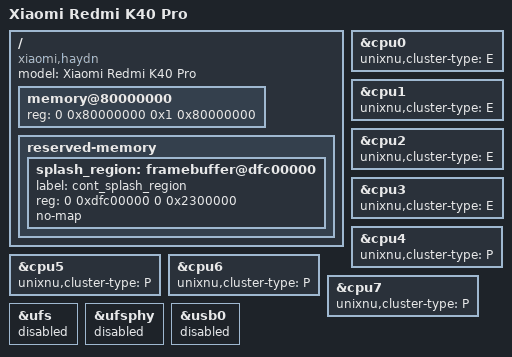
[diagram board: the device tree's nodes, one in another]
// SPDX-License-Identifier: BSD-3-Clause
// Xiaomi Redmi K40 Pro / K40 Pro+ / Mi 11i (haydn), Qualcomm SM8350.
// Hardware values come from the device's own firmware FDT (/sys/firmware/fdt)
// and the on-device GPT; see docs/haydn-hardware.md.
/dts-v1/;
/include/ "sm8350.dtsi"

/ {
    model = "Xiaomi Redmi K40 Pro";
    compatible = "xiaomi,haydn", "qcom,sm8350";
    // Restated here: with the legacy /include/ directive dtc parses this
    // file's nodes before it has merged the included root, so a 64-bit "reg"
    // size below would be truncated to 32 bits without these two lines.
    #address-cells = <2>;
    #size-cells = <2>;

    memory@80000000 {
        device_type = "memory";
        // The ADT window published to XNU. The board has 12 GiB split as
        // 0x80000000+0x37500000, 0xc0000000+0x140000000, 0x200000000+0x180000000.
        // One flat 6 GiB window from 0x80000000 stays inside real DRAM and
        // matches [payload] dram_size (mkadt rejects a mismatch).
        // 0x180000000 needs 33 bits, so it is written as two cells:
        // <address-hi address-lo size-hi size-lo>.
        reg = <0 0x80000000 0x1 0x80000000>;
    };

    reserved-memory {
        #address-cells = <2>;
        #size-cells = <2>;
        ranges;
        splash_region: framebuffer@dfc00000 {
            label = "cont_splash_region";
            reg = <0 0xdfc00000 0 0x2300000>;
            no-map;
        };
    };
};

// Big cores drive the P cluster, the four A55 cores the E cluster.
&cpu0 { unixnu,cluster-type = "E"; };
&cpu1 { unixnu,cluster-type = "E"; };
&cpu2 { unixnu,cluster-type = "E"; };
&cpu3 { unixnu,cluster-type = "E"; };
&cpu4 { unixnu,cluster-type = "P"; };
&cpu5 { unixnu,cluster-type = "P"; };
&cpu6 { unixnu,cluster-type = "P"; };
&cpu7 { unixnu,cluster-type = "P"; };

// Storage and USB stay disabled until the matching native drivers exist.
&ufs { status = "disabled"; };
&ufsphy { status = "disabled"; };
&usb0 { status = "disabled"; };
